AUTOSAR XML (schema 00048)
package /VehicleProject
  system System
    system mapping System_MPPNG
    root-software-compositions:
      root sw composition prototype EcuSwComposition: software-composition=ECU_Composition
package /ECUCompositionTypes
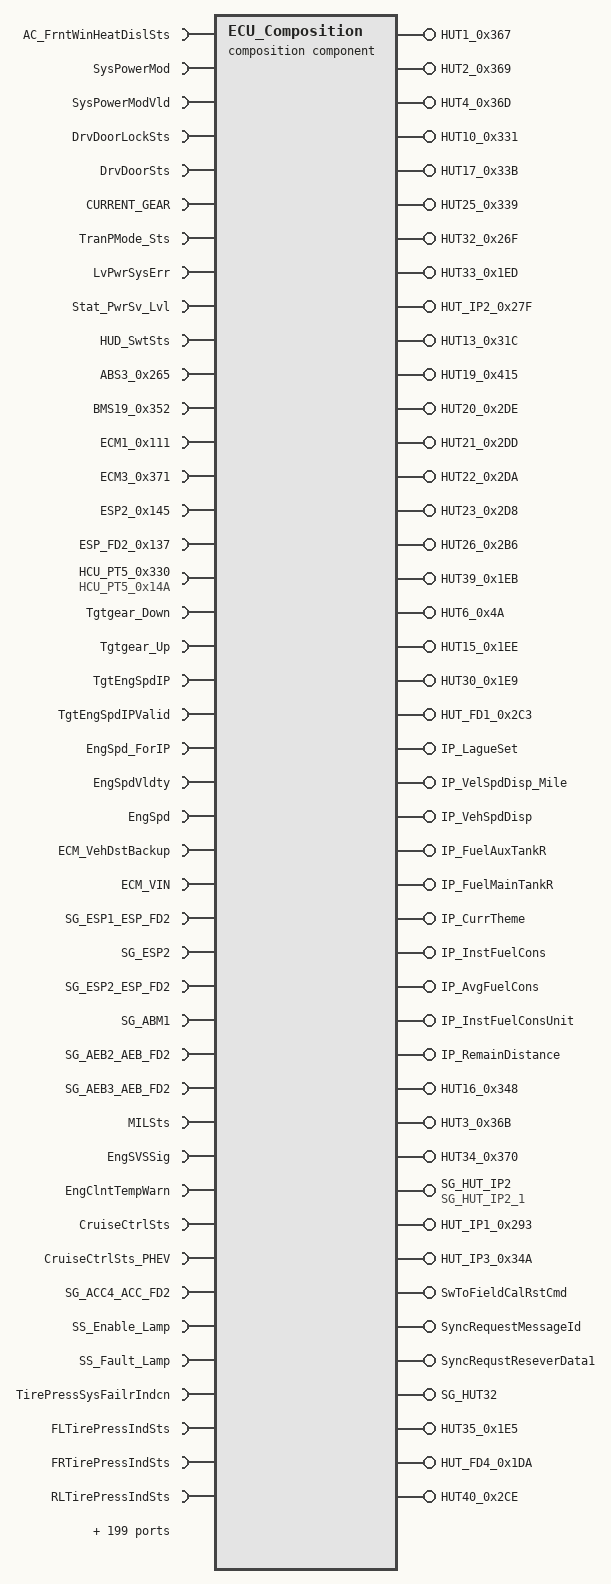
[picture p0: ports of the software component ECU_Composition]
  composition sw component type ECU_Composition
    79 x require port:
      AC_FrntWinHeatDislSts: nonqueued-receiver-com-spec{data-element=AC_FrntWinHeatDislSts, init-value=0}, required-interface=AC_FrntWinHeatDislSts
      SysPowerMod: nonqueued-receiver-com-spec{data-element=SysPowerMod, init-value=0}, required-interface=SysPowerMod
      SysPowerModVld: nonqueued-receiver-com-spec{data-element=SysPowerModVld, init-value=0}, required-interface=SysPowerModVld
      DrvDoorLockSts: nonqueued-receiver-com-spec{data-element=DrvDoorLockSts, init-value=0}, required-interface=DrvDoorLockSts
      DrvDoorSts: nonqueued-receiver-com-spec{data-element=DrvDoorSts, init-value=0}, required-interface=DrvDoorSts
      CURRENT_GEAR: nonqueued-receiver-com-spec{data-element=CURRENT_GEAR, init-value=0}, required-interface=CURRENT_GEAR
      TranPMode_Sts: nonqueued-receiver-com-spec{data-element=TranPMode_Sts, init-value=0}, required-interface=TranPMode_Sts
      LvPwrSysErr: nonqueued-receiver-com-spec{data-element=LvPwrSysErr, init-value=0}, required-interface=LvPwrSysErr
      Stat_PwrSv_Lvl: nonqueued-receiver-com-spec{data-element=Stat_PwrSv_Lvl, init-value=0}, required-interface=Stat_PwrSv_Lvl
      HUD_SwtSts: nonqueued-receiver-com-spec{data-element=HUD_SwtSts, init-value=1}, required-interface=HUD_SwtSts
      ABS3_0x265: nonqueued-receiver-com-spec{data-element=ABS3_0x265, init-value=16 x 0}, required-interface=ABS3_0x265
      BMS19_0x352: nonqueued-receiver-com-spec{data-element=BMS19_0x352, init-value=8 x 0}, required-interface=BMS19_0x352
      ECM1_0x111: nonqueued-receiver-com-spec{data-element=ECM1_0x111, init-value=8 x 0}, required-interface=ECM1_0x111
      ECM3_0x371: nonqueued-receiver-com-spec{data-element=ECM3_0x371, init-value=8 x 0}, required-interface=ECM3_0x371
      ESP2_0x145: nonqueued-receiver-com-spec{data-element=ESP2_0x145, init-value=16 x 0}, required-interface=ESP2_0x145
      ESP_FD2_0x137: nonqueued-receiver-com-spec{data-element=ESP_FD2_0x137, init-value=64 x 0}, required-interface=ESP_FD2_0x137
      HCU_PT5_0x330: nonqueued-receiver-com-spec{data-element=HCU_PT5_0x14A, init-value=8 x 0}, required-interface=HCU_PT5_0x14A
      Tgtgear_Down: nonqueued-receiver-com-spec{data-element=Tgtgear_Down, init-value=0}, required-interface=Tgtgear_Down
      Tgtgear_Up: nonqueued-receiver-com-spec{data-element=Tgtgear_Up, init-value=0}, required-interface=Tgtgear_Up
      TgtEngSpdIP: nonqueued-receiver-com-spec{data-element=TgtEngSpdIP, init-value=0}, required-interface=TgtEngSpdIP
      TgtEngSpdIPValid: nonqueued-receiver-com-spec{data-element=TgtEngSpdIPValid, init-value=0}, required-interface=TgtEngSpdIPValid
      EngSpd_ForIP: nonqueued-receiver-com-spec{data-element=EngSpd_ForIP, init-value=0}, required-interface=EngSpd_ForIP
      EngSpdVldty: nonqueued-receiver-com-spec{data-element=EngSpdVldty, init-value=2}, required-interface=EngSpdVldty
      EngSpd: nonqueued-receiver-com-spec{data-element=EngSpd, init-value=0}, required-interface=EngSpd
      ECM_VehDstBackup: nonqueued-receiver-com-spec{data-element=ECM_VehDstBackup, init-value=0}, required-interface=ECM_VehDstBackup
      ECM_VIN: nonqueued-receiver-com-spec{data-element=ECM19_0x3B5, init-value=8 x 0}, required-interface=ECM_VIN
      SG_ESP1_ESP_FD2: nonqueued-receiver-com-spec{data-element=SG_ESP1_ESP_FD2, uses-end-to-end-protection=true, alive-timeout=0.2, enable-update=true, handle-never-received=true, init-value=fields=[BTCActv_0x137:0, CheckSum_ESP1_0x137:0, dummy_ESP_FD2_16:0, dummy_ESP_FD2_17:0, dummy_ESP_FD2_18:0, dummy_ESP_FD2_19:0, dummy_ESP_FD2_20:0, ESP_MasterCylBrkPress_0x137:0, ESP_MasterCylBrkPressVld_0x137:0, ESPActvInfoLmp_0x137:0, ESPBrkLmpCtrl_0x137:0, ESPFailSts_0x137:0, ESPFuncOffSts_0x137:0, MSRActv_0x137:0, PTCActv_0x137:0, RollingCounter_ESP1_0x137:0, VDCActv_0x137:0]}, required-interface=SG_ESP1_ESP_FD2
      SG_ESP2: nonqueued-receiver-com-spec{data-element=SG_ESP2, uses-end-to-end-protection=true, alive-timeout=0.2, enable-update=true, handle-never-received=true, init-value=fields=[DrivingModDis:0, DrivingModReq_ESP:0, TAB_Available:0, TAB_Sts:0, ABAActv_0x145:0, ABAavailable_0x145:0, ABPActv_0x145:0, ABPAvailable_0x145:0, AEBAvailable_0x145:0, AEBBAActv_0x145:0, AEBIBActv_0x145:0, AVHErrSts_0x145:0, AVHSts_0x145:0, AWBActv_0x145:0, AWBAvailable_0x145:0, BrkDskOvrheatd_0x145:0, CDDActv_0x145:0, CDDAvailable_0x145:0, CDPActv_0x145:0, CheckSum_ESP2_0x145:0, dummy_ESP2_0:0, dummy_ESP2_1:0, dummy_ESP2_2:0, dummy_ESP2_3:0, dummy_ESP2_4:0, dummy_ESP2_5:0, dummy_ESP2_6:0, dummy_ESP2_7:0, HDCCtrl_0x145:0, HDCFault_0x145:0, NoBrkForce_0x145:0, RollingCounter_ESP2_0x145:0, VehStandstill_0x145:0]}, required-interface=SG_ESP2
      SG_ESP2_ESP_FD2: nonqueued-receiver-com-spec{data-element=SG_ESP2_ESP_FD2, uses-end-to-end-protection=true, alive-timeout=0.2, enable-update=true, handle-never-received=true, init-value=fields=[ABAActv_0x137:0, ABAavailable_0x137:0, ABPActv_0x137:0, ABPAvailable_0x137:0, AEBAvailable_0x137:0, AEBBAActv_0x137:0, AEBIBActv_0x137:0, AVHErrSts_0x137:0, AVHSts_0x137:0, AWBActv_0x137:0, AWBAvailable_0x137:0, BrkDskOvrheatd_0x137:0, CDDActv_0x137:0, CDDAvailable_0x137:0, CDPActv_0x137:0, CheckSum_ESP2_0x137:0, dummy_ESP_FD2_8:0, dummy_ESP_FD2_9:0, dummy_ESP_FD2_10:0, dummy_ESP_FD2_11:0, dummy_ESP_FD2_12:0, dummy_ESP_FD2_13:0, dummy_ESP_FD2_14:0, dummy_ESP_FD2_15:0, HDCCtrl_0x137:0, HDCFault_0x137:0, NoBrkForce_0x137:0, RollingCounter_ESP2_0x137:0, VehStandstill_0x137:0]}, required-interface=SG_ESP2_ESP_FD2
      SG_ABM1: nonqueued-receiver-com-spec{data-element=SG_ABM1, uses-end-to-end-protection=true, alive-timeout=5, enable-update=true, handle-never-received=true, init-value=fields=[AirbFailLmpCmd:1, CheckSum_ABM1:0, DrvSBR:1, DrvSBR_Visual:1, PassSBR:1, PassSBR_Visual:1, RollingCounter_ABM1:0, SecRowLSBR:1, SecRowLSBR_Visual:1, SecRowMidSBR:1, SecRowMidSBR_Visual:1, SecRowRSBR:1, SecRowRSBR_Visual:1, CrashOutputSts:0, dummy_ABM1_0:0, dummy_ABM1_1:0, dummy_ABM1_2:0, dummy_ABM1_3:0, dummy_ABM1_4:0, dummy_ABM1_5:0]}, required-interface=SG_ABM1
      SG_AEB2_AEB_FD2: nonqueued-receiver-com-spec{data-element=SG_AEB2_AEB_FD2, uses-end-to-end-protection=true, alive-timeout=0.5, enable-update=true, handle-never-received=true, init-value=fields=[AEB_JA_Resp:1, AEB_PedResp:1, AEB_VehResp:1, Checksum_AEB2:0, FCW_Snvty:0, RollingCounter_AEB2:0, dummy_AEB_FD2_8:0, dummy_AEB_FD2_9:0, dummy_AEB_FD2_10:0, dummy_AEB_FD2_11:0, dummy_AEB_FD2_12:0, dummy_AEB_FD2_13:0, dummy_AEB_FD2_14:0]}, required-interface=SG_AEB2_AEB_FD2
      SG_AEB3_AEB_FD2: nonqueued-receiver-com-spec{data-element=SG_AEB3_AEB_FD2, uses-end-to-end-protection=true, alive-timeout=0.5, enable-update=true, handle-never-received=true, init-value=fields=[AEB_JA_Warn:0, AEB_JABrkTrig:0, AEB_JAFuncSts:0, AEB_PedTrig:0, AEB_VehTrig:0, Checksum_AEB3:0, FCW_AEB_PedFctSts:0, FCW_AEB_VehFctSts:0, FCW_Warn:0, RollingCounter_AEB3:0, dummy_AEB_FD2_15:0, dummy_AEB_FD2_16:0, dummy_AEB_FD2_17:0, dummy_AEB_FD2_18:0, dummy_AEB_FD2_19:0, dummy_AEB_FD2_20:0, dummy_AEB_FD2_21:0]}, required-interface=SG_AEB3_AEB_FD2
      MILSts: nonqueued-receiver-com-spec{data-element=MILSts, init-value=0}, required-interface=MILSts
      EngSVSSig: nonqueued-receiver-com-spec{data-element=EngSVSSig, init-value=0}, required-interface=EngSVSSig
      EngClntTempWarn: nonqueued-receiver-com-spec{data-element=EngClntTempWarn, init-value=0}, required-interface=EngClntTempWarn
      CruiseCtrlSts: nonqueued-receiver-com-spec{data-element=CruiseCtrlSts, init-value=0}, required-interface=CruiseCtrlSts
      CruiseCtrlSts_PHEV: nonqueued-receiver-com-spec{data-element=CruiseCtrlSts_PHEV, init-value=0}, required-interface=CruiseCtrlSts_PHEV
      SG_ACC4_ACC_FD2: nonqueued-receiver-com-spec{data-element=SG_ACC4_ACC_FD2, uses-end-to-end-protection=true, alive-timeout=1, enable-update=true, handle-never-received=true, init-value=fields=[ACC_FctSts:0, ACC_InterSysInfoDisp:0, ACC_ModDisp:0, ACC_ObjDetecte:0, ACC_SpdSetValue:255, ACC_TakeOverReq:0, ACC_TgtObjBarDisp:0, ACC_TimeGapSet:0, Checksum_ACC4:0, ISL_InterSysInfoDisp:0, RollingCounter_ACC4:0, TJA_ACC_SelSts:0, TJA_ICA_InterSysInfoDisp:0, TJA_ICA_ModDisp:0, CruCha_ModDisp:0, CruChar_InterSysInfoDisp:0, Longctrl_HazActv:0, dummy_ACC_FD2_8:0, dummy_ACC_FD2_9:0, dummy_ACC_FD2_10:0]}, required-interface=SG_ACC4_ACC_FD2
      SS_Enable_Lamp: nonqueued-receiver-com-spec{data-element=SS_Enable_Lamp, init-value=0}, required-interface=SS_Enable_Lamp
      SS_Fault_Lamp: nonqueued-receiver-com-spec{data-element=SS_Fault_Lamp, init-value=0}, required-interface=SS_Fault_Lamp
      TirePressSysFailrIndcn: nonqueued-receiver-com-spec{data-element=TirePressSysFailrIndcn, init-value=0}, required-interface=TirePressSysFailrIndcn
      FLTirePressIndSts: nonqueued-receiver-com-spec{data-element=FLTirePressIndSts, init-value=0}, required-interface=FLTirePressIndSts
      FRTirePressIndSts: nonqueued-receiver-com-spec{data-element=FRTirePressIndSts, init-value=0}, required-interface=FRTirePressIndSts
      RLTirePressIndSts: nonqueued-receiver-com-spec{data-element=RLTirePressIndSts, init-value=0}, required-interface=RLTirePressIndSts
      RRTirePressIndSts: nonqueued-receiver-com-spec{data-element=RRTirePressIndSts, init-value=0}, required-interface=RRTirePressIndSts
      FLTireTempSts: nonqueued-receiver-com-spec{data-element=FLTireTempSts, init-value=0}, required-interface=FLTireTempSts
      FRTireTempSts: nonqueued-receiver-com-spec{data-element=FRTireTempSts, init-value=0}, required-interface=FRTireTempSts
      RLTireTempSts: nonqueued-receiver-com-spec{data-element=RLTireTempSts, init-value=0}, required-interface=RLTireTempSts
      RRTireTempSts: nonqueued-receiver-com-spec{data-element=RRTireTempSts, init-value=0}, required-interface=RRTireTempSts
      SG_EPS1_FD1: nonqueued-receiver-com-spec{data-element=SG_EPS1_FD1, uses-end-to-end-protection=true, alive-timeout=0.2, enable-update=true, handle-never-received=true, init-value=fields=[CheckSum_EPS1_0x147:0, dummy_EPS_FD1_0:0, dummy_EPS_FD1_1:0, dummy_EPS_FD1_2:0, dummy_EPS_FD1_3:0, dummy_EPS_FD1_4:0, dummy_EPS_FD1_5:0, dummy_EPS_FD1_6:0, dummy_EPS_FD1_7:0, EPS_FailSts_0x147:0, EPS_SteerMod_0x147:0, EPS_TrqSnsrSts_0x147:0, RollingCounter_EPS1_0x147:0]}, required-interface=SG_EPS1_FD1
      SG_IFC4_IFC_FD2: nonqueued-receiver-com-spec{data-element=SG_IFC4_IFC_FD2, uses-end-to-end-protection=true, alive-timeout=0.5, enable-update=true, handle-never-received=true, init-value=fields=[CameraBlockageSts:0, Checksum_IFC4:0, ELKMainState:0, IFC_Handsoffwarn:0, IFCCalibrationSts:0, LaneAvailability:0, LDW_LKAWarn:0, LSSErrSts:0, LSSFuncSts:0, LSSIntervention:0, RollingCounter_IFC4:0, TJA_FollowSts:0, AESintervention:0, ESSintervention:0, dummy_IFC_FD2_13:0, dummy_IFC_FD2_14:0, dummy_IFC_FD2_15:0, ELKActSts:0, IntelligentEvaActSts:0, LCKStsIndcr:0]}, required-interface=SG_IFC4_IFC_FD2
      ESP_HMI_WarningOn: nonqueued-receiver-com-spec{data-element=ESP_HMI_WarningOn, init-value=0}, required-interface=ESP_HMI_WarningOn
      IB_Warn: nonqueued-receiver-com-spec{data-element=IB_Warn, init-value=0}, required-interface=IB_Warn
      FFogLmpSts_F_Pbox: nonqueued-receiver-com-spec{data-element=FFogLmpSts_F_Pbox, init-value=0}, required-interface=FFogLmpSts_F_Pbox
      RFogLmpFailSts_R_Pbox: nonqueued-receiver-com-spec{data-element=RFogLmpFailSts_R_Pbox, init-value=0}, required-interface=RFogLmpFailSts_R_Pbox
      SG_HC1: nonqueued-receiver-com-spec{data-element=SG_HC1, uses-end-to-end-protection=true, alive-timeout=1, enable-update=true, handle-never-received=true, init-value=fields=[ADBstatus:0, ALS_FailSts:0, Checksum_HC1:0, HighBeamSts_HC:0, LeftHighBeamFailSts:0, LeftLowBeamFailSts:0, RightHighBeamFailSts:0, RightLowBeamFailSts:0, RollingCounter_HC1:0, dummy_HC1_0:0, dummy_HC1_1:0, dummy_HC1_2:0, dummy_HC1_3:0, dummy_HC1_4:0, dummy_HC1_5:0]}, required-interface=SG_HC1
      LTurnLmpFailSts: nonqueued-receiver-com-spec{data-element=LTurnLmpFailSts, init-value=0}, required-interface=LTurnLmpFailSts
      LTurnLmpSts_R_Pbox: nonqueued-receiver-com-spec{data-element=LTurnLmpSts_R_Pbox, init-value=0}, required-interface=LTurnLmpSts_R_Pbox
      RTurnLmpSts_R_Pbox: nonqueued-receiver-com-spec{data-element=RTurnLmpSts_R_Pbox, init-value=0}, required-interface=RTurnLmpSts_R_Pbox
      PosnLmpOutpSts_R_Pbox: nonqueued-receiver-com-spec{data-element=PosnLmpOutpSts_R_Pbox, init-value=0}, required-interface=PosnLmpOutpSts_R_Pbox
      TrailerSts: nonqueued-receiver-com-spec{data-element=TrailerSts, init-value=0}, required-interface=TrailerSts
      HiLowBeamSts: nonqueued-receiver-com-spec{data-element=HiLowBeamSts, init-value=0}, required-interface=HiLowBeamSts
      HCU_EVLmpSts: nonqueued-receiver-com-spec{data-element=HCU_EVLmpSts, init-value=0}, required-interface=HCU_EVLmpSts
      HCU_ChrgSysLmpSts: nonqueued-receiver-com-spec{data-element=HCU_ChrgSysLmpSts, init-value=0}, required-interface=HCU_ChrgSysLmpSts
      ParkLmpSts_R_Pbox: nonqueued-receiver-com-spec{data-element=ParkLmpSts_R_Pbox, init-value=0}, required-interface=ParkLmpSts_R_Pbox
      TgtRcprtnTrqSts: nonqueued-receiver-com-spec{data-element=TgtRcprtnTrqSts, init-value=0}, required-interface=TgtRcprtnTrqSts
      CCO_Active: nonqueued-receiver-com-spec{data-element=CCO_Active, init-value=0}, required-interface=CCO_Active
      RSDS_CTA_Actv: nonqueued-receiver-com-spec{data-element=RSDS_CTA_Actv, init-value=0}, required-interface=RSDS_CTA_Actv
      RSDS_ErrSts: nonqueued-receiver-com-spec{data-element=RSDS_ErrSts, init-value=0}, required-interface=RSDS_ErrSts
      RemoteModSts: nonqueued-receiver-com-spec{data-element=RemoteModSts, init-value=0}, required-interface=RemoteModSts
      KL30BRelaySts: nonqueued-receiver-com-spec{data-element=KL30BRelaySts, init-value=0}, required-interface=KL30BRelaySts
      BMS_SOCLowWarn: nonqueued-receiver-com-spec{data-element=BMS_SOCLowWarn, init-value=0}, required-interface=BMS_SOCLowWarn
      TSRSts: nonqueued-receiver-com-spec{data-element=TSRSts, init-value=0}, required-interface=TSRSts
      TSRSpdLimSts: nonqueued-receiver-com-spec{data-element=TSRSpdLimSts, init-value=0}, required-interface=TSRSpdLimSts
      TSRSpdLim: nonqueued-receiver-com-spec{data-element=TSRSpdLim, init-value=0}, required-interface=TSRSpdLim
      TSRSpdLimWarn: nonqueued-receiver-com-spec{data-element=TSRSpdLimWarn, init-value=0}, required-interface=TSRSpdLimWarn
      TSRTrfcSignVal: nonqueued-receiver-com-spec{data-element=TSRTrfcSignVal, init-value=0}, required-interface=TSRTrfcSignVal
      AC2_0x385: nonqueued-receiver-com-spec{data-element=AC2_0x385, init-value=8 x 0}, required-interface=AC2_0x385
      AC1_0x29D: nonqueued-receiver-com-spec{data-element=AC1_0x29D, init-value=8 x 0}, required-interface=AC1_0x29D
    provide port HUT1_0x367: nonqueued-sender-com-spec{data-element=HUT1_0x367, init-value=8 x 0}, provided-interface=HUT1_0x367
    42 x require port:
      ACC_FD2_0x2AB: nonqueued-receiver-com-spec{data-element=ACC_FD2_0x2AB, init-value=64 x 0}, required-interface=ACC_FD2_0x2AB
      AEB_FD2_0x227: nonqueued-receiver-com-spec{data-element=AEB_FD2_0x227, init-value=64 x 0}, required-interface=AEB_FD2_0x227
      BCM1_0x319: nonqueued-receiver-com-spec{data-element=BCM1_0x319, init-value=16 x 0}, required-interface=BCM1_0x319
      BCM3_0x345: nonqueued-receiver-com-spec{data-element=BCM3_0x345, init-value=16 x 0}, required-interface=BCM3_0x345
      BCM8_0x29F: nonqueued-receiver-com-spec{data-element=BCM8_0x29F, init-value=8 x 0}, required-interface=BCM8_0x29F
      BMS4_0xF1: nonqueued-receiver-com-spec{data-element=BMS4_0xF1, init-value=8 x 0}, required-interface=BMS4_0xF1
      BMS30_0x3F1: nonqueued-receiver-com-spec{data-element=BMS30_0x3F1, init-value=8 x 0}, required-interface=BMS30_0x3F1
      BMS35_0x2C4: nonqueued-receiver-com-spec{data-element=BMS35_0x2C4, init-value=8 x 0}, required-interface=BMS35_0x2C4
      CP1_0x35E: nonqueued-receiver-com-spec{data-element=CP1_0x35E, init-value=8 x 0}, required-interface=CP1_0x35E
      CSA1_0x165: nonqueued-receiver-com-spec{data-element=CSA1_0x165, init-value=8 x 0}, required-interface=CSA1_0x165
      CSA2_0xA1: nonqueued-receiver-com-spec{data-element=CSA2_0xA1, init-value=8 x 0}, required-interface=CSA2_0xA1
      CSA3_0x244: nonqueued-receiver-com-spec{data-element=CSA3_0x244, init-value=8 x 0}, required-interface=CSA3_0x244
      DCT5_0x221: nonqueued-receiver-com-spec{data-element=DCT5_0x221, init-value=8 x 0}, required-interface=DCT5_0x221
      DCT7_0x235: nonqueued-receiver-com-spec{data-element=DCT7_0x235, init-value=16 x 0}, required-interface=DCT7_0x235
      DDCM1_0x2CA: nonqueued-receiver-com-spec{data-element=DDCM1_0x2CA, init-value=8 x 0}, required-interface=DDCM1_0x2CA
      DHT_FD1_0xC1: nonqueued-receiver-com-spec{data-element=DHT_FD1_0xC1, init-value=64 x 0}, required-interface=DHT_FD1_0xC1
      DMS_FD1_0x24D: nonqueued-receiver-com-spec{data-element=DMS_FD1_0x24D, init-value=64 x 0}, required-interface=DMS_FD1_0x24D
      ECM2_0x271: nonqueued-receiver-com-spec{data-element=ECM2_0x271, init-value=8 x 0}, required-interface=ECM2_0x271
      ECM_PT7_0x117: nonqueued-receiver-com-spec{data-element=ECM_PT7_0x117, init-value=8 x 0}, required-interface=ECM_PT7_0x117
      EEM1_0x2A8: nonqueued-receiver-com-spec{data-element=EEM1_0x2A8, init-value=8 x 0}, required-interface=EEM1_0x2A8
      ELD1_0x152: nonqueued-receiver-com-spec{data-element=ELD1_0x152, init-value=8 x 0}, required-interface=ELD1_0x152
      EPB1_0x16B: nonqueued-receiver-com-spec{data-element=EPB1_0x16B, init-value=8 x 0}, required-interface=EPB1_0x16B
      EPS1_0x168: nonqueued-receiver-com-spec{data-element=EPS1_0x168, init-value=8 x 0}, required-interface=EPS1_0x168
      EPS_FD1_0x147: nonqueued-receiver-com-spec{data-element=EPS_FD1_0x147, init-value=64 x 0}, required-interface=EPS_FD1_0x147
      ESCL2_0x303: nonqueued-receiver-com-spec{data-element=ESCL2_0x303, init-value=8 x 0}, required-interface=ESCL2_0x303
      ESP1_0x149: nonqueued-receiver-com-spec{data-element=ESP1_0x149, init-value=16 x 0}, required-interface=ESP1_0x149
      ESP8_0x170: nonqueued-receiver-com-spec{data-element=ESP8_0x170, init-value=8 x 0}, required-interface=ESP8_0x170
      ESP10_0xD8: nonqueued-receiver-com-spec{data-element=ESP10_0xD8, init-value=8 x 0}, required-interface=ESP10_0xD8
      ESP11_0xC8: nonqueued-receiver-com-spec{data-element=ESP11_0xC8, init-value=8 x 0}, required-interface=ESP11_0xC8
      F_PBox1_0x19B: nonqueued-receiver-com-spec{data-element=F_PBox1_0x19B, init-value=8 x 0}, required-interface=F_PBox1_0x19B
      FPAS1_0x26D: nonqueued-receiver-com-spec{data-element=FPAS1_0x26D, init-value=8 x 0}, required-interface=FPAS1_0x26D
      Haldex1_0x251: nonqueued-receiver-com-spec{data-element=Haldex1_0x251, init-value=8 x 0}, required-interface=Haldex1_0x251
      HAP_FD1_0x15B: nonqueued-receiver-com-spec{data-element=HAP_FD1_0x15B, init-value=64 x 0}, required-interface=HAP_FD1_0x15B
      HAP_FD2_0x274: nonqueued-receiver-com-spec{data-element=HAP_FD2_0x274, init-value=64 x 0}, required-interface=HAP_FD2_0x274
      HAP_FD3_0x298: nonqueued-receiver-com-spec{data-element=HAP_FD3_0x298, init-value=64 x 0}, required-interface=HAP_FD3_0x298
      HC1_0x287: nonqueued-receiver-com-spec{data-element=HC1_0x287, init-value=8 x 0}, required-interface=HC1_0x287
      HCU_HC6_0x314: nonqueued-receiver-com-spec{data-element=HCU_HC6_0x314, init-value=8 x 0}, required-interface=HCU_HC6_0x314
      HCU_HC7_0x3C2: nonqueued-receiver-com-spec{data-element=HCU_HC7_0x3C2, init-value=8 x 0}, required-interface=HCU_HC7_0x3C2
      HCU_PT4_0x2FA: nonqueued-receiver-com-spec{data-element=HCU_PT4_0x2FA, init-value=8 x 0}, required-interface=HCU_PT4_0x2FA
      HCU_PT7_0x248: nonqueued-receiver-com-spec{data-element=HCU_PT7_0x248, init-value=8 x 0}, required-interface=HCU_PT7_0x248
      HCU_PT8_0x1C0: nonqueued-receiver-com-spec{data-element=HCU_PT8_0x1C0, init-value=8 x 0}, required-interface=HCU_PT8_0x1C0
      HUD1_0x325: nonqueued-receiver-com-spec{data-element=HUD1_0x325, init-value=8 x 0}, required-interface=HUD1_0x325
    8 x provide port:
      HUT2_0x369: nonqueued-sender-com-spec{data-element=HUT2_0x369, init-value=8 x 0}, provided-interface=HUT2_0x369
      HUT4_0x36D: nonqueued-sender-com-spec{data-element=HUT4_0x36D, init-value=8 x 0}, provided-interface=HUT4_0x36D
      HUT10_0x331: nonqueued-sender-com-spec{data-element=HUT10_0x331, init-value=8 x 0}, provided-interface=HUT10_0x331
      HUT17_0x33B: nonqueued-sender-com-spec{data-element=HUT17_0x33B, init-value=8 x 0}, provided-interface=HUT17_0x33B
      HUT25_0x339: nonqueued-sender-com-spec{data-element=HUT25_0x339, init-value=8 x 0}, provided-interface=HUT25_0x339
      HUT32_0x26F: nonqueued-sender-com-spec{data-element=HUT32_0x26F, init-value=8 x 0}, provided-interface=HUT32_0x26F
      HUT33_0x1ED: nonqueued-sender-com-spec{data-element=HUT33_0x1ED, init-value=8 x 0}, provided-interface=HUT33_0x1ED
      HUT_IP2_0x27F: nonqueued-sender-com-spec{data-element=HUT_IP2_0x27F, init-value=16 x 0}, provided-interface=HUT_IP2_0x27F
    60 x require port:
      Ibooster_FD2_0x120: nonqueued-receiver-com-spec{data-element=Ibooster_FD2_0x120, init-value=64 x 0}, required-interface=Ibooster_FD2_0x120
      IFC_FD3_0x2CF: nonqueued-receiver-com-spec{data-element=IFC_FD3_0x2CF, init-value=64 x 0}, required-interface=IFC_FD3_0x2CF
      OBC1_0x316: nonqueued-receiver-com-spec{data-element=OBC1_0x316, init-value=8 x 0}, required-interface=OBC1_0x316
      OBC2_0x317: nonqueued-receiver-com-spec{data-element=OBC2_0x317, init-value=8 x 0}, required-interface=OBC2_0x317
      PDCM1_0x2CD: nonqueued-receiver-com-spec{data-element=PDCM1_0x2CD, init-value=8 x 0}, required-interface=PDCM1_0x2CD
      PEPS2_0x295: nonqueued-receiver-com-spec{data-element=PEPS2_0x295, init-value=8 x 0}, required-interface=PEPS2_0x295
      PEPS4_0x302: nonqueued-receiver-com-spec{data-element=PEPS4_0x302, init-value=8 x 0}, required-interface=PEPS4_0x302
      R_PBox1_0x19C: nonqueued-receiver-com-spec{data-element=R_PBox1_0x19C, init-value=16 x 0}, required-interface=R_PBox1_0x19C
      RPAS1_0x26E: nonqueued-receiver-com-spec{data-element=RPAS1_0x26E, init-value=8 x 0}, required-interface=RPAS1_0x26E
      RSDS_FD1_0x16F: nonqueued-receiver-com-spec{data-element=RSDS_FD1_0x16F, init-value=64 x 0}, required-interface=RSDS_FD1_0x16F
      SCM1_0x2D1: nonqueued-receiver-com-spec{data-element=SCM1_0x2D1, init-value=8 x 0}, required-interface=SCM1_0x2D1
      T_Box_FD1_0x33: nonqueued-receiver-com-spec{data-element=T_Box_FD1_0x33, init-value=16 x 0}, required-interface=T_Box_FD1_0x33
      T_Box_FD3_0x3E9: nonqueued-receiver-com-spec{data-element=T_Box_FD3_0x3E9, init-value=16 x 0}, required-interface=T_Box_FD3_0x3E9
      TPMS1_0x341: nonqueued-receiver-com-spec{data-element=TPMS1_0x341, init-value=16 x 0}, required-interface=TPMS1_0x341
      TPMS2_0x395: nonqueued-receiver-com-spec{data-element=TPMS2_0x395, init-value=16 x 0}, required-interface=TPMS2_0x395
      Trailer1_0x273: nonqueued-receiver-com-spec{data-element=Trailer1_0x273, init-value=8 x 0}, required-interface=Trailer1_0x273
      VSG1_0x2E1: nonqueued-receiver-com-spec{data-element=VSG1_0x2E1, init-value=8 x 0}, required-interface=VSG1_0x2E1
      WPC1_0x2BA: nonqueued-receiver-com-spec{data-element=WPC1_0x2BA, init-value=8 x 0}, required-interface=WPC1_0x2BA
      SG_IFC5_IFC_FD2: nonqueued-receiver-com-spec{data-element=SG_IFC5_IFC_FD2, init-value=fields=[Checksum_IFC5:0, IFC_LaneCurve:2047, IFC_LeLane_dy:2496, IFC_LeLaneTyp:0, IFC_NextLeLaneTyp:0, IFC_NextRiLaneTyp:0, IFC_RiLane_dy:2496, IFC_RiLaneTyp:0, RollingCounter_IFC5:0, dummy_IFC_FD2_16:0]}, required-interface=SG_IFC5_IFC_FD2
      RSDS_IPSoundReq: nonqueued-receiver-com-spec{data-element=RSDS_IPSoundReq, init-value=0}, required-interface=RSDS_IPSoundReq
      TSRSpdLimCfdc: nonqueued-receiver-com-spec{data-element=TSRSpdLimCfdc, init-value=0}, required-interface=TSRSpdLimCfdc
      PASWorkCmd: nonqueued-receiver-com-spec{data-element=PASWorkCmd, init-value=0}, required-interface=PASWorkCmd
      APS_FLSideSnsrFailSts: nonqueued-receiver-com-spec{data-element=APS_FLSideSnsrFailSts, init-value=0}, required-interface=APS_FLSideSnsrFailSts
      APS_FRSideSnsrFailSts: nonqueued-receiver-com-spec{data-element=APS_FRSideSnsrFailSts, init-value=0}, required-interface=APS_FRSideSnsrFailSts
      APS_RLSideSnsrFailSts: nonqueued-receiver-com-spec{data-element=APS_RLSideSnsrFailSts, init-value=0}, required-interface=APS_RLSideSnsrFailSts
      APS_RRSideSnsrFailSts: nonqueued-receiver-com-spec{data-element=APS_RRSideSnsrFailSts, init-value=0}, required-interface=APS_RRSideSnsrFailSts
      SDW_SoundIndcn: nonqueued-receiver-com-spec{data-element=SDW_SoundIndcn, init-value=0}, required-interface=SDW_SoundIndcn
      SDWActiveSts: nonqueued-receiver-com-spec{data-element=SDWActiveSts, init-value=0}, required-interface=SDWActiveSts
      APS_WorkSts: nonqueued-receiver-com-spec{data-element=APS_WorkSts, init-value=0}, required-interface=APS_WorkSts
      APS_SysSoundIndcn: nonqueued-receiver-com-spec{data-element=APS_SysSoundIndcn, init-value=0}, required-interface=APS_SysSoundIndcn
      RPAS_WorkSts_FD: nonqueued-receiver-com-spec{data-element=RPAS_WorkSts_FD, init-value=0}, required-interface=RPAS_WorkSts_FD
      RPAS_SoundIndcn_FD: nonqueued-receiver-com-spec{data-element=RPAS_SoundIndcn_FD, init-value=0}, required-interface=RPAS_SoundIndcn_FD
      FLTirePress: nonqueued-receiver-com-spec{data-element=FLTirePress, init-value=0}, required-interface=FLTirePress
      FRTirePress: nonqueued-receiver-com-spec{data-element=FRTirePress, init-value=0}, required-interface=FRTirePress
      FRTireTemp: nonqueued-receiver-com-spec{data-element=FRTireTemp, init-value=0}, required-interface=FRTireTemp
      FLTireTemp: nonqueued-receiver-com-spec{data-element=FLTireTemp, init-value=0}, required-interface=FLTireTemp
      RLTireTemp: nonqueued-receiver-com-spec{data-element=RLTireTemp, init-value=0}, required-interface=RLTireTemp_1
      RLTirePress: nonqueued-receiver-com-spec{data-element=RLTirePress, init-value=0}, required-interface=RLTirePress_1
      RRTirePress: nonqueued-receiver-com-spec{data-element=RRTirePress, init-value=0}, required-interface=RRTirePress
      RRTireTemp: nonqueued-receiver-com-spec{data-element=RRTireTemp, init-value=0}, required-interface=RRTireTemp
      IFC_FD2_0x23D: nonqueued-receiver-com-spec{data-element=IFC_FD2_0x23D, init-value=64 x 0}, required-interface=IFC_FD2_0x23D
      ABM1_0x351: nonqueued-receiver-com-spec{data-element=ABM1_0x351, init-value=16 x 0}, required-interface=ABM1_0x351
      BMS_IntelEngIdlChrgnSts: nonqueued-receiver-com-spec{data-element=BMS_IntelEngIdlChrgnSts, init-value=0}, required-interface=BMS_IntelEngIdlChrgnSts_1
      BMS_BattHeatRunaway: nonqueued-receiver-com-spec{data-element=BMS_BattHeatRunaway, init-value=0}, required-interface=BMS_BattHeatRunaway_1
      GentrWarnLmpSts: nonqueued-receiver-com-spec{data-element=GentrWarnLmpSts, init-value=0}, required-interface=GentrWarnLmpSts
      FPAS_SoundIndcn_FD: nonqueued-receiver-com-spec{data-element=FPAS_SoundIndcn_FD, init-value=0}, required-interface=FPAS_SoundIndcn_FD
      FPAS_WorkSts_FD: nonqueued-receiver-com-spec{data-element=FPAS_WorkSts_FD, init-value=0}, required-interface=FPAS_WorkSts_FD
      TGS_LEVER: nonqueued-receiver-com-spec{data-element=TGS_LEVER, init-value=14}, required-interface=TGS_LEVER
      IFC_FD5_0x19F: nonqueued-receiver-com-spec{data-element=IFC_FD5_0x19F, init-value=64 x 0}, required-interface=IFC_FD5_0x19F
      IFC_FD6_0x222: nonqueued-receiver-com-spec{data-element=IFC_FD6_0x222, init-value=64 x 0}, required-interface=IFC_FD6_0x222
      CR_FD1_0x15E: nonqueued-receiver-com-spec{data-element=CR_FD1_0x15E, init-value=64 x 0}, required-interface=CR_FD1_0x15E
      AntitheftSts: nonqueued-receiver-com-spec{data-element=AntitheftSts, init-value=0}, required-interface=AntitheftSts
      AMP2_0x3E3: nonqueued-receiver-com-spec{data-element=AMP2_0x3E3, init-value=16 x 0}, required-interface=AMP2_0x3E3
      AMP3_0x3E5: nonqueued-receiver-com-spec{data-element=AMP3_0x3E5, init-value=8 x 0}, required-interface=AMP3_0x3E5
      BCM12_0x238: nonqueued-receiver-com-spec{data-element=BCM12_0x238, init-value=8 x 0}, required-interface=BCM12_0x238
      DSM1_0x2C1: nonqueued-receiver-com-spec{data-element=DSM1_0x2C1, init-value=8 x 0}, required-interface=DSM1_0x2C1
      GW_FD1_0x2BB: nonqueued-receiver-com-spec{data-element=GW_FD1_0x2BB, init-value=64 x 0}, required-interface=GW_FD1_0x2BB
      RPAS2_0x2ED: nonqueued-receiver-com-spec{data-element=RPAS2_0x2ED, init-value=8 x 0}, required-interface=RPAS2_0x2ED
      RSDS_FD2_0x30A: nonqueued-receiver-com-spec{data-element=RSDS_FD2_0x30A, init-value=64 x 0}, required-interface=RSDS_FD2_0x30A
      TMCU_FD3_0x3C9: nonqueued-receiver-com-spec{data-element=TMCU_FD3_0x3C9, init-value=8 x 0}, required-interface=TMCU_FD3_0x3C9
    12 x provide port:
      HUT13_0x31C: nonqueued-sender-com-spec{data-element=HUT13_0x31C, init-value=8 x 0}, provided-interface=HUT13_0x31C
      HUT19_0x415: nonqueued-sender-com-spec{data-element=HUT19_0x415, init-value=8 x 0}, provided-interface=HUT19_0x415
      HUT20_0x2DE: nonqueued-sender-com-spec{data-element=HUT20_0x2DE, init-value=8 x 0}, provided-interface=HUT20_0x2DE
      HUT21_0x2DD: nonqueued-sender-com-spec{data-element=HUT21_0x2DD, init-value=8 x 0}, provided-interface=HUT21_0x2DD
      HUT22_0x2DA: nonqueued-sender-com-spec{data-element=HUT22_0x2DA, init-value=8 x 0}, provided-interface=HUT22_0x2DA
      HUT23_0x2D8: nonqueued-sender-com-spec{data-element=HUT23_0x2D8, init-value=8 x 0}, provided-interface=HUT23_0x2D8
      HUT26_0x2B6: nonqueued-sender-com-spec{data-element=HUT26_0x2B6, init-value=8 x 0}, provided-interface=HUT26_0x2B6
      HUT39_0x1EB: nonqueued-sender-com-spec{data-element=HUT39_0x1EB, init-value=8 x 0}, provided-interface=HUT39_0x1EB
      HUT6_0x4A: nonqueued-sender-com-spec{data-element=HUT6_0x4A, init-value=8 x 0}, provided-interface=HUT6_0x4A
      HUT15_0x1EE: nonqueued-sender-com-spec{data-element=HUT15_0x1EE, init-value=16 x 0}, provided-interface=HUT15_0x1EE
      HUT30_0x1E9: nonqueued-sender-com-spec{data-element=HUT30_0x1E9, init-value=8 x 0}, provided-interface=HUT30_0x1E9
      HUT_FD1_0x2C3: nonqueued-sender-com-spec{data-element=HUT_FD1_0x2C3, init-value=64 x 0}, provided-interface=HUT_FD1_0x2C3
    11 x require port:
      TMCU_ActSpd_RM: nonqueued-receiver-com-spec{data-element=TMCU_ActSpd_RM, init-value=20000}, required-interface=TMCU_ActSpd_RM
      FuelConsumption: nonqueued-receiver-com-spec{data-element=FuelConsumption, init-value=0}, required-interface=FuelConsumption
      FCTA_Warn: nonqueued-receiver-com-spec{data-element=FCTA_Warn, init-value=0}, required-interface=FCTA_Warn
      FCTBTrig: nonqueued-receiver-com-spec{data-element=FCTBTrig, init-value=0}, required-interface=FCTBTrig
      CR_BliSts: nonqueued-receiver-com-spec{data-element=CR_BliSts, init-value=0}, required-interface=CR_BliSts
      FCTA_B_FuncSts: nonqueued-receiver-com-spec{data-element=FCTA_B_FuncSts, init-value=0}, required-interface=FCTA_B_FuncSts
      SG_ACC8_ACC_FD2: nonqueued-receiver-com-spec{data-element=SG_ACC8_ACC_FD2, init-value=fields=[ADAS_DriverInloop_Monitor:0, Checksum_ACC8:0, HWA_InterSysInfoDisp:0, HWA_LaneChange:0, HWA_LaneChangeReq:0, HWA_ModDisp:0, HWA_warning:0, Longctrl_HCUTrqReq_DVR:0, RollingCounter_ACC8:0, dummy_ACC_FD2_11:0, dummy_ACC_FD2_12:0, dummy_ACC_FD2_13:0, dummy_ACC_FD2_14:0, dummy_ACC_FD2_15:0]}, required-interface=SG_ACC8_ACC_FD2
      SG_IFC3_IFC_FD2: nonqueued-receiver-com-spec{data-element=SG_IFC3_IFC_FD2, init-value=fields=[AESErrSts:0, AESResp:0, AESSts:0, Checksum_IFC3:0, ELKResp:0, ESS_Pedresp:0, ESS_Vehresp:0, ESSErrSts:0, ESSSts:0, IFCHUTInterface:0, IntelligentEvaResp:0, LCKResp:0, LDW_LKA_Snvty:0, LDWResp:0, LKAResp:0, LSSResp:0, LSSWarnFormResp:0, RollingCounter_IFC3:0, dummy_IFC_FD2_8:0, dummy_IFC_FD2_9:0, dummy_IFC_FD2_10:0, dummy_IFC_FD2_11:0, dummy_IFC_FD2_12:0]}, required-interface=SG_IFC3_IFC_FD2
      SG_ACC3_ACC_FD2: nonqueued-receiver-com-spec{data-element=SG_ACC3_ACC_FD2, init-value=fields=[ALC_InterSysInfoDisp:0, ALC_Resp:0, Checksum_ACC3:0, HWA_Resp:0, HWA_SnvtySet_Resp:0, ICA_HandsOffResp:0, ISL_Resp:0, Longctrl_Decel_Req_DVR:0, Longctrl_Decel_ReqValue_DVR:0, Longctrl_DecelToStopReq_DVR:0, Longctrl_DrvOFF_Req_DVR:0, Longctrl_EngTrqReq_DVR:32767, Longctrl_EngTrqReqActive_DVR:0, Longctrl_HCUTrqReqActive_DVR:0, Longctrl_ModSts_DVR:0, Longctrl_ParkShiftReq_DVR:0, Longctrl_VehHldReq_DVR:0, RollingCounter_ACC3:0, dummy_ACC_FD2_4:0, dummy_ACC_FD2_5:0, dummy_ACC_FD2_6:0, dummy_ACC_FD2_7:0]}, required-interface=SG_ACC3_ACC_FD2
      EngCoolantTemp: nonqueued-receiver-com-spec{data-element=EngCoolantTemp, init-value=0}, required-interface=EngCoolantTemp
      EngClntTempVldty: nonqueued-receiver-com-spec{data-element=EngClntTempVldty, init-value=2}, required-interface=EngClntTempVldty
    10 x provide port:
      IP_LagueSet: nonqueued-sender-com-spec{data-element=IP_LagueSet, init-value=15}, provided-interface=IP_LagueSet
      IP_VelSpdDisp_Mile: nonqueued-sender-com-spec{data-element=IP_VelSpdDisp_Mile, init-value=0}, provided-interface=IP_VelSpdDisp_Mile
      IP_VehSpdDisp: nonqueued-sender-com-spec{data-element=IP_VehSpdDisp, init-value=0}, provided-interface=IP_VehSpdDisp
      IP_FuelAuxTankR: nonqueued-sender-com-spec{data-element=IP_FuelAuxTankR, init-value=10}, provided-interface=IP_FuelAuxTankR
      IP_FuelMainTankR: nonqueued-sender-com-spec{data-element=IP_FuelMainTankR, init-value=10}, provided-interface=IP_FuelMainTankR
      IP_CurrTheme: nonqueued-sender-com-spec{data-element=IP_CurrTheme, init-value=4}, provided-interface=IP_CurrTheme
      IP_InstFuelCons: nonqueued-sender-com-spec{data-element=IP_InstFuelCons, init-value=16383}, provided-interface=IP_InstFuelCons
      IP_AvgFuelCons: nonqueued-sender-com-spec{data-element=IP_AvgFuelCons, init-value=4095}, provided-interface=IP_AvgFuelCons
      IP_InstFuelConsUnit: nonqueued-sender-com-spec{data-element=IP_InstFuelConsUnit, init-value=0}, provided-interface=IP_InstFuelConsUnit
      IP_RemainDistance: nonqueued-sender-com-spec{data-element=IP_RemainDistance, init-value=0}, provided-interface=IP_RemainDistance
    5 x require port:
      ACC_FD3_0x2B4: nonqueued-receiver-com-spec{data-element=ACC_FD3_0x2B4, init-value=64 x 0}, required-interface=ACC_FD3_0x2B4
      ABS1_0x231: nonqueued-receiver-com-spec{data-element=ABS1_0x231, init-value=8 x 0}, required-interface=ABS1_0x231
      ABS2_0x246: nonqueued-receiver-com-spec{data-element=ABS2_0x246, init-value=8 x 0}, required-interface=ABS2_0x246
      BCM6_0x28C: nonqueued-receiver-com-spec{data-element=BCM6_0x28C, init-value=8 x 0}, required-interface=BCM6_0x28C
      PLG_1_0x2FE: nonqueued-receiver-com-spec{data-element=PLG_1_0x2FE, init-value=8 x 0}, required-interface=PLG_1_0x2FE
    provide port HUT16_0x348: nonqueued-sender-com-spec{data-element=HUT16_0x348, init-value=8 x 0}, provided-interface=HUT16_0x348
    provide port HUT3_0x36B: nonqueued-sender-com-spec{data-element=HUT3_0x36B, init-value=8 x 0}, provided-interface=HUT3_0x36B
    provide port HUT34_0x370: nonqueued-sender-com-spec{data-element=HUT34_0x370, init-value=8 x 0}, provided-interface=HUT34_0x370
    5 x require port:
      SG_EPB1: nonqueued-receiver-com-spec{data-element=SG_EPB1, uses-end-to-end-protection=true, alive-timeout=0.2, enable-update=true, handle-never-received=true, init-value=fields=[CheckSum_EPB1:0, EPBErrSts:0, EPBRedLmpSts:0, EPBSts:0, EPBTextDisp:0, PressBrakePedalPointOut:0, RollingCounter_EPB1:0, dummy_EPB1_0:0, dummy_EPB1_1:0, dummy_EPB1_2:0, dummy_EPB1_3:0, dummy_EPB1_4:0, dummy_EPB1_5:0, dummy_EPB1_6:0, dummy_EPB1_7:0]}, required-interface=SG_EPB1
      SG_EPS1: nonqueued-receiver-com-spec{data-element=SG_EPS1, uses-end-to-end-protection=true, alive-timeout=0.2, enable-update=true, handle-never-received=true, init-value=fields=[CheckSum_EPS1_0x168:0, dummy_EPS1_0:0, dummy_EPS1_1:0, dummy_EPS1_2:0, dummy_EPS1_3:0, dummy_EPS1_4:0, dummy_EPS1_5:0, dummy_EPS1_6:0, dummy_EPS1_7:0, EPS_FailSts_0x168:0, EPS_SteerMod_0x168:0, EPS_TrqSnsrSts_0x168:1, RollingCounter_EPS1_0x168:0]}, required-interface=SG_EPS1
      SG_DCT7: nonqueued-receiver-com-spec{data-element=SG_DCT7, uses-end-to-end-protection=true, alive-timeout=0.5, enable-update=true, handle-never-received=true, init-value=fields=[CheckSum_DCT7:0, DCT_PrsBrk_Warn:0, DCT_RaceModeSts:0, DCT_ShftNotAlwd_Warn:0, DCT_ShftRecom_M:0, DrvAutoGearDisp:0, DrvWarnMsg:0, RollingCounter_DCT7:0, DrvFaiMsg_0x235:0, DrvGearDispSts_0x235:0, DrvModDisp_0x235:0, DrvModDispSts_0x235:0, dummy_DCT7_0:0, dummy_DCT7_1:0, dummy_DCT7_2:0, dummy_DCT7_3:0, dummy_DCT7_4:0, dummy_DCT7_5:0]}, required-interface=SG_DCT7
      SG_ABS3: nonqueued-receiver-com-spec{data-element=SG_ABS3, uses-end-to-end-protection=true, alive-timeout=0.2, enable-update=true, handle-never-received=true, init-value=fields=[ABSActv_0x265:0, ABSFailSts_0x265:1, CheckSum_ABS3_0x265:0, dummy_ABS3_0:0, dummy_ABS3_1:0, dummy_ABS3_2:0, dummy_ABS3_3:0, EBDActv_0x265:0, EBDFailSts_0x265:0, RollingCounter_ABS3_0x265:0, VehOdoInfo_0x265:0, VehOdoInfoSts_0x265:1, VehSpd_0x265:0, VehSpdVld_0x265:0]}, required-interface=SG_ABS3
      SG_ESP1: nonqueued-receiver-com-spec{data-element=SG_ESP1, uses-end-to-end-protection=true, alive-timeout=0.2, enable-update=true, handle-never-received=true, init-value=fields=[BTCActv_0x149:0, CheckSum_ESP1_0x149:0, dummy_ESP1_0:0, dummy_ESP1_1:0, dummy_ESP1_2:0, dummy_ESP1_3:0, dummy_ESP1_4:0, ESP_MasterCylBrkPress_0x149:0, ESP_MasterCylBrkPressVld_0x149:1, ESPActvInfoLmp_0x149:0, ESPBrkLmpCtrl_0x149:0, ESPFailSts_0x149:0, ESPFuncOffSts_0x149:0, MSRActv_0x149:0, PTCActv_0x149:0, RollingCounter_ESP1_0x149:0, VDCActv_0x149:0]}, required-interface=SG_ESP1
    provide port SG_HUT_IP2: nonqueued-sender-com-spec{data-element=SG_HUT_IP2, uses-end-to-end-protection=true, init-value=fields=[CheckSum_IP2:0, IP_ABMWarnLmpFailrSts:0, IP_ACCErr:0, IP_BattChrgLmpSts:0, IP_DrvSeatBeltWarnLmpFailSts:0, IP_EngOilPressLowLmpSts:0, IP_Err:0, IP_FuelLvlInfo:0, IP_FuelLvlLowLmpSts:0, IP_PassSeatBeltWarnLmpFailSts:0, IP_VehSpdUnit:0, IP_VehTotDistance:0, IP_VehTotDistanceValid:0, IP_VINcompr:0, RollingCounter_IP2:0]}, provided-interface=SG_HUT_IP2_1
    require port SG_ABS3_ESP_FD2: nonqueued-receiver-com-spec{data-element=SG_ABS3_ESP_FD2, uses-end-to-end-protection=true, alive-timeout=0.2, enable-update=true, handle-never-received=true, init-value=fields=[ABSActv_0x137:0, ABSFailSts_0x137:1, CheckSum_ABS3_0x137:0, dummy_ESP_FD2_37:0, dummy_ESP_FD2_38:0, dummy_ESP_FD2_39:0, dummy_ESP_FD2_40:0, EBDActv_0x137:0, EBDFailSts_0x137:0, RollingCounter_ABS3_0x137:0, VehOdoInfo_0x137:0, VehOdoInfoSts_0x137:1, VehSpd_0x137:0, VehSpdVld_0x137:0]}, required-interface=SG_ABS3_ESP_FD2
    provide port HUT_IP1_0x293: nonqueued-sender-com-spec{data-element=HUT_IP1_0x293, init-value=8 x 0}, provided-interface=HUT_IP1_0x293
    provide port HUT_IP3_0x34A: nonqueued-sender-com-spec{data-element=HUT_IP3_0x34A, init-value=16 x 0}, provided-interface=HUT_IP3_0x34A
    8 x require port:
      SG_ACC7_ACC_FD2: nonqueued-receiver-com-spec{data-element=SG_ACC7_ACC_FD2, uses-end-to-end-protection=true, alive-timeout=1, enable-update=true, handle-never-received=true, init-value=fields=[ACC_LeTargrtDection:0, ACC_LeTgtDx:0, ACC_LeTgtDy:0, ACC_LeTgtTyp:0, ACC_RiTargrtDetn:0, ACC_RiTgtDx:0, ACC_RiTgtDy:0, ACC_RiTgtTyp:0, Checksum_ACC7:0, dummy_ACC_FD2_19:0, dummy_ACC_FD2_20:0, Request_driveoff:0, RollingCounter_ACC7:0]}, required-interface=SG_ACC7_ACC_FD2
      T_Box_SysErrSts: nonqueued-receiver-com-spec{data-element=T_Box_SysErrSts, init-value=0}, required-interface=T_Box_SysErrSts
      BSD_LCA_warningReqleft: nonqueued-receiver-com-spec{data-element=BSD_LCA_warningReqleft, init-value=0}, required-interface=BSD_LCA_warningReqleft
      BSD_LCA_warningReqRight: nonqueued-receiver-com-spec{data-element=BSD_LCA_warningReqRight, init-value=0}, required-interface=BSD_LCA_warningReqRight
      RCTA_warningReqLeft: nonqueued-receiver-com-spec{data-element=RCTA_warningReqLeft, init-value=0}, required-interface=RCTA_warningReqLeft
      RCTA_warningReqRight: nonqueued-receiver-com-spec{data-element=RCTA_warningReqRight, init-value=0}, required-interface=RCTA_warningReqRight
      DOW_warningReqleft: nonqueued-receiver-com-spec{data-element=DOW_warningReqleft, init-value=0}, required-interface=DOW_warningReqleft
      DOW_warningReqRight: nonqueued-receiver-com-spec{data-element=DOW_warningReqRight, init-value=0}, required-interface=DOW_warningReqRight
    provide port SwToFieldCalRstCmd: nonqueued-sender-com-spec{data-element=SwToFieldCalRstCmd, init-value=0}, provided-interface=SwToFieldCalRstCmd
    provide port SyncRequestMessageId: nonqueued-sender-com-spec{data-element=SyncRequestMessageId, init-value=0}, provided-interface=SyncRequestMessageId
    provide port SyncRequstReseverData1: nonqueued-sender-com-spec{data-element=SyncRequstReseverData1, init-value=7 x 0}, provided-interface=SyncRequstReseverData1
    require port DCT3_0xA6: nonqueued-receiver-com-spec{data-element=DCT3_0xA6, init-value=8 x 0}, required-interface=DCT3_0xA6
    require port ECM11_0x2D3: nonqueued-receiver-com-spec{data-element=ECM11_0x2D3, init-value=8 x 0}, required-interface=ECM11_0x2D3
    provide port SG_HUT32: nonqueued-sender-com-spec{data-element=SG_HUT32, uses-end-to-end-protection=true, init-value=fields=[CheckSum_HUT32:0, ContnPrkgReq:0, ContnPrkgReqValid:0, DetVideoLost:0, PrkgCtrlModReq:0, PrkgCtrlModReqValid:0, PrkStraightContinueReq_HUT:0, PrkStraightModSel_HUT:0, PrkStraightStrtReq_HUT:0, PrkStraightSts_HUT:0, PrkStraightSuspendOrFinishReq_HUT:0, PrkStraightSwtReq_HUT:0, PrkStraightVehStrtReq_HUT_Valid:0, RollingCounter_HUT32:0, ScrnOpSts:0, VolLampDispSts:0, XLvl:2047, YLvl:2047]}, provided-interface=SG_HUT32
    10 x require port:
      AdjVolUpSwtSts: nonqueued-receiver-com-spec{data-element=AdjVolUpSwtSts, init-value=0}, required-interface=AdjVolUpSwtSts
      PageUpSwtSts: nonqueued-receiver-com-spec{data-element=PageUpSwtSts, init-value=0}, required-interface=PageUpSwtSts
      ACC_FD4_0x2B8: nonqueued-receiver-com-spec{data-element=ACC_FD4_0x2B8, alive-timeout=1, enable-update=true, handle-never-received=true, init-value=64 x 0}, required-interface=ACC_FD4_0x2B8
      SG_ACC6_ACC_FD2: nonqueued-receiver-com-spec{data-element=SG_ACC6_ACC_FD2, uses-end-to-end-protection=true, alive-timeout=1, enable-update=true, handle-never-received=true, init-value=fields=[ACC_EgoStatus:0, ACC_PotentialTgtDetn:0, ACC_PotentialTgtDx:0, ACC_PotentialTgtDy:0, ACC_PotentialTgtTyp:0, ACC_RlvTgtDetn:0, ACC_RlvTgtDx:0, ACC_RlvTgtDy:0, ACC_RlvTgtTyp:0, Checksum_ACC6:0, dummy_ACC_FD2_16:0, dummy_ACC_FD2_17:0, dummy_ACC_FD2_18:0, RollingCounter_ACC6:0]}, required-interface=SG_ACC6_ACC_FD2
      SG_BMS4: nonqueued-receiver-com-spec{data-element=SG_BMS4, uses-end-to-end-protection=true, alive-timeout=0.1, enable-update=true, handle-never-received=true, init-value=fields=[BMS_BattPoweErr:0, BMS_ErrCategory:0, BMS_PackCurr:0, BMS_PackVolt:178, BMS_PowerDownCmplt:0, CheckSum_BMS4:0, dummy_BMS4_0:0, dummy_BMS4_1:0, dummy_BMS4_2:0, dummy_BMS4_3:0, dummy_BMS4_4:0, RollingCounter_BMS4:0]}, required-interface=SG_BMS4
      SG_HCU_HP5: nonqueued-receiver-com-spec{data-element=SG_HCU_HP5, uses-end-to-end-protection=true, alive-timeout=0.5, enable-update=true, handle-never-received=true, init-value=fields=[Checksum_HCU_HP5:0, DrvFaiMsg_0x201:0, DrvGearDisp:0, DrvGearDispSts_0x201:0, DrvModDisp_0x201:0, DrvModDispSts_0x201:0, dummy_HCU_HP5_0:0, dummy_HCU_HP5_1:0, dummy_HCU_HP5_2:0, dummy_HCU_HP5_3:0, dummy_HCU_HP5_4:0, HCU_EnrgFlowInd_DHT:0, HCU_PrsBrkWarn:0, HCU_ShftNotAlwd_Warn:0, RollingCounter_HCU_HP5:0]}, required-interface=SG_HCU_HP5
      SG_HCU_PT4: nonqueued-receiver-com-spec{data-element=SG_HCU_PT4, uses-end-to-end-protection=true, alive-timeout=1, enable-update=true, handle-never-received=true, init-value=fields=[CarWashMode_Sts:0, CarWashMode_StsDisp:0, Checksum_HCU_PT4:0, dummy_HCU_PT4_0:0, dummy_HCU_PT4_1:0, dummy_HCU_PT4_2:0, dummy_HCU_PT4_3:0, dummy_HCU_PT4_4:0, dummy_HCU_PT4_5:0, dummy_HCU_PT4_6:0, dummy_HCU_PT4_7:0, HCU_ACStsReq:2, HCU_BattPowerRedWarn:0, HCU_ConnectChrgLine_Indcn:0, HCU_EgyRecFB:0, HCU_EnerSavePowerMod:0, HCU_InhbChrgInfo:0, HCU_OilTankCoverSts:0, HCU_OPDFail:0, HCU_RefuReq:0, HCU_RemoveChrgLine_Indcn:0, HCU_Shift_P_Indcn:0, HCU_SOCLow_Indcn:0, HCU_WadeModeSetSts:0, OPDParkWarnReq:0, RollingCounter_HCU_PT4:0]}, required-interface=SG_HCU_PT4
      SG_HCU_PT7: nonqueued-receiver-com-spec{data-element=SG_HCU_PT7, uses-end-to-end-protection=true, alive-timeout=0.5, enable-update=true, handle-never-received=true, init-value=fields=[CheckSum_HCU_PT7:0, dummy_HCU_PT7_0:0, dummy_HCU_PT7_1:0, dummy_HCU_PT7_2:0, dummy_HCU_PT7_3:0, dummy_HCU_PT7_4:0, dummy_HCU_PT7_5:0, dummy_HCU_PT7_6:0, HCU_12VSysErr_1:0, HCU_12VSysErr_2:0, HCU_12VSysErrLmpSts:0, HCU_EnrgFlowInd:0, HCU_HybSysErr_1:0, HCU_HybSysErr_2:0, HCU_HybSysErr_3:0, HCU_HybSysErr_4:0, HCU_HybSysErr_5:0, HCU_HybSysErr_6:0, HCU_HybSysErr_7:0, HCU_HybSysErrLmpSts:0, HCU_ModSwtFail:0, HCU_OPDLmpSts:0, HCU_OPDSts:0, HCU_PowerRedWarnLmpCmd:0, HCU_RdyLmpSts:0, RollingCounter_HCU_PT7:0]}, required-interface=SG_HCU_PT7
      SG_DHT_FD1: nonqueued-receiver-com-spec{data-element=SG_DHT_FD1, uses-end-to-end-protection=true, alive-timeout=0.1, enable-update=true, handle-never-received=true, init-value=fields=[CheckSum_DHT1:0, dummy_DHT_FD1_8:0, dummy_DHT_FD1_9:0, dummy_DHT_FD1_10:0, dummy_DHT_FD1_11:0, dummy_DHT_FD1_12:0, dummy_DHT_FD1_13:0, RollingCounter_DHT1:0, TCU_ClutchHotWarning:0, TCU_ErrCategory:0]}, required-interface=SG_DHT_FD1
      SG_IFC6_IFC_FD2: nonqueued-receiver-com-spec{data-element=SG_IFC6_IFC_FD2, uses-end-to-end-protection=true, alive-timeout=0.5, enable-update=true, handle-never-received=true, init-value=fields=[Checksum_IFC6:0, dummy_IFC_FD2_17:0, dummy_IFC_FD2_18:0, dummy_IFC_FD2_19:0, dummy_IFC_FD2_20:0, IFC_NextLeLane_dy:2496, IFC_NextRiLane_dy:2496, RollingCounter_IFC6:0]}, required-interface=SG_IFC6_IFC_FD2
    provide port HUT35_0x1E5: nonqueued-sender-com-spec{data-element=HUT35_0x1E5, init-value=8 x 0}, provided-interface=HUT35_0x1E5
    provide port HUT_FD4_0x1DA: nonqueued-sender-com-spec{data-element=HUT_FD4_0x1DA, init-value=64 x 0}, provided-interface=HUT_FD4_0x1DA
    require port HAP_FD6_0x289: nonqueued-receiver-com-spec{data-element=HAP_FD6_0x289, alive-timeout=1, enable-update=true, handle-never-received=true, init-value=64 x 0}, required-interface=HAP_FD6_0x289
    require port HAP_FD7_0x29B: nonqueued-receiver-com-spec{data-element=HAP_FD7_0x29B, alive-timeout=1, enable-update=true, handle-never-received=true, init-value=64 x 0}, required-interface=HAP_FD7_0x29B
    provide port HUT40_0x2CE: nonqueued-sender-com-spec{data-element=HUT40_0x2CE, init-value=8 x 0}, provided-interface=HUT40_0x2CE
    18 x require port:
      HCM_L1_0x308: nonqueued-receiver-com-spec{data-element=HCM_L1_0x308, alive-timeout=2, enable-update=true, handle-never-received=true, init-value=8 x 0}, required-interface=HCM_L1_0x308
      HCM_R1_0x30D: nonqueued-receiver-com-spec{data-element=HCM_R1_0x30D, alive-timeout=2, enable-update=true, handle-never-received=true, init-value=8 x 0}, required-interface=HCM_R1_0x30D
      BMS22_0x3BF: nonqueued-receiver-com-spec{data-element=BMS22_0x3BF, alive-timeout=10, enable-update=true, handle-never-received=true, init-value=8 x 0}, required-interface=BMS22_0x3BF
      BMS8_0x285: nonqueued-receiver-com-spec{data-element=BMS8_0x285, alive-timeout=1, enable-update=true, handle-never-received=true, init-value=8 x 0}, required-interface=BMS8_0x285
      BMS_FD14_0x1E3: nonqueued-receiver-com-spec{data-element=BMS_FD14_0x1E3, init-value=8 x 0}, required-interface=BMS_FD14_0x1E3
      HCU_FD1_0x60: nonqueued-receiver-com-spec{data-element=HCU_FD1_0x60, alive-timeout=0.1, enable-update=true, handle-never-received=true, init-value=64 x 0}, required-interface=HCU_FD1_0x60
      HCU_HC3_0x268: nonqueued-receiver-com-spec{data-element=HCU_HC3_0x268, alive-timeout=0.5, enable-update=true, handle-never-received=true, init-value=8 x 0}, required-interface=HCU_HC3_0x268
      HCU_HC8_0x1E2: nonqueued-receiver-com-spec{data-element=HCU_HC8_0x1E2, init-value=8 x 0}, required-interface=HCU_HC8_0x1E2
      HCU_HP5_0x201: nonqueued-receiver-com-spec{data-element=HCU_HP5_0x201, alive-timeout=0.5, enable-update=true, handle-never-received=true, init-value=8 x 0}, required-interface=HCU_HP5_0x201
      HCU_HP6_0x11A: nonqueued-receiver-com-spec{data-element=HCU_HP6_0x11A, alive-timeout=0.2, enable-update=true, handle-never-received=true, init-value=8 x 0}, required-interface=HCU_HP6_0x11A
      FPAS_WorkSts: nonqueued-receiver-com-spec{data-element=FPAS_WorkSts, alive-timeout=1, enable-update=true, handle-never-received=true, init-value=0}, required-interface=FPAS_WorkSts
      FPAS_SoundIndcn: nonqueued-receiver-com-spec{data-element=FPAS_SoundIndcn, alive-timeout=1, enable-update=true, handle-never-received=true, init-value=0}, required-interface=FPAS_SoundIndcn
      RPAS_SoundIndcn: nonqueued-receiver-com-spec{data-element=RPAS_SoundIndcn, alive-timeout=1, enable-update=true, handle-never-received=true, init-value=0}, required-interface=RPAS_SoundIndcn
      RPAS_WorkSts: nonqueued-receiver-com-spec{data-element=RPAS_WorkSts, alive-timeout=1, enable-update=true, handle-never-received=true, init-value=0}, required-interface=RPAS_WorkSts
      LADBstatus: nonqueued-receiver-com-spec{data-element=LADBstatus, alive-timeout=2, enable-update=true, handle-never-received=true, init-value=0}, required-interface=LADBstatus
      RADBstatus: nonqueued-receiver-com-spec{data-element=RADBstatus, alive-timeout=2, enable-update=true, handle-never-received=true, init-value=0}, required-interface=RADBstatus
      LHiBeamSts: nonqueued-receiver-com-spec{data-element=LHiBeamSts, alive-timeout=2, enable-update=true, handle-never-received=true, init-value=0}, required-interface=LHiBeamSts
      RHiBeamSts: nonqueued-receiver-com-spec{data-element=RHiBeamSts, alive-timeout=2, enable-update=true, handle-never-received=true, init-value=0}, required-interface=RHiBeamSts
    component Cluster_App: type=Cluster_App
    component BSW_CDD: type=BSW_CDD
    component Manager_Swc: type=Manager_Swc
    delegate Cluster_App.SG_ESP1_ESP_FD2 <-> outer port SG_ESP1_ESP_FD2
    delegate Cluster_App.SG_ESP2 <-> outer port SG_ESP2
    delegate Cluster_App.SG_ESP2_ESP_FD2 <-> outer port SG_ESP2_ESP_FD2
    delegate Cluster_App.SG_ABM1 <-> outer port SG_ABM1
    delegate Cluster_App.SG_AEB2_AEB_FD2 <-> outer port SG_AEB2_AEB_FD2
    delegate Cluster_App.SG_AEB3_AEB_FD2 <-> outer port SG_AEB3_AEB_FD2
    delegate Cluster_App.SG_ACC4_ACC_FD2 <-> outer port SG_ACC4_ACC_FD2
    delegate Cluster_App.SG_EPS1_FD1 <-> outer port SG_EPS1_FD1
    delegate Cluster_App.SG_IFC4_IFC_FD2 <-> outer port SG_IFC4_IFC_FD2
    delegate Cluster_App.SG_HC1 <-> outer port SG_HC1
    delegate Cluster_App.SG_IFC5_IFC_FD2 <-> outer port SG_IFC5_IFC_FD2
    delegate Cluster_App.IFC_FD2_0x23D <-> outer port IFC_FD2_0x23D
    delegate Cluster_App.ABM1_0x351 <-> outer port ABM1_0x351
    delegate Cluster_App.BMS_BattHeatRunaway <-> outer port BMS_BattHeatRunaway
    delegate Cluster_App.GentrWarnLmpSts <-> outer port GentrWarnLmpSts
    delegate Cluster_App.FPAS_SoundIndcn_FD <-> outer port FPAS_SoundIndcn_FD
    delegate Cluster_App.FPAS_WorkSts_FD <-> outer port FPAS_WorkSts_FD
    delegate Cluster_App.TGS_LEVER <-> outer port TGS_LEVER
    delegate Cluster_App.FuelConsumption <-> outer port FuelConsumption
    delegate Cluster_App.FCTA_Warn <-> outer port FCTA_Warn
    delegate Cluster_App.FCTBTrig <-> outer port FCTBTrig
    delegate Cluster_App.CR_BliSts <-> outer port CR_BliSts
    delegate Cluster_App.FCTA_B_FuncSts <-> outer port FCTA_B_FuncSts
    delegate Cluster_App.SG_ACC8_ACC_FD2 <-> outer port SG_ACC8_ACC_FD2
    delegate Cluster_App.SG_IFC3_IFC_FD2 <-> outer port SG_IFC3_IFC_FD2
    delegate Cluster_App.SG_ACC3_ACC_FD2 <-> outer port SG_ACC3_ACC_FD2
    delegate Cluster_App.SG_EPB1 <-> outer port SG_EPB1
    delegate Cluster_App.SG_EPS1 <-> outer port SG_EPS1
    delegate Cluster_App.SG_DCT7 <-> outer port SG_DCT7
    delegate Cluster_App.SG_ABS3 <-> outer port SG_ABS3
    delegate Cluster_App.SG_ESP1 <-> outer port SG_ESP1
    delegate Cluster_App.SG_HUT_IP2 <-> outer port SG_HUT_IP2
    delegate Cluster_App.SG_ABS3_ESP_FD2 <-> outer port SG_ABS3_ESP_FD2
    delegate Cluster_App.SG_ACC7_ACC_FD2 <-> outer port SG_ACC7_ACC_FD2
    delegate Cluster_App.T_Box_SysErrSts <-> outer port T_Box_SysErrSts
    delegate Cluster_App.BSD_LCA_warningReqleft <-> outer port BSD_LCA_warningReqleft
    delegate Cluster_App.BSD_LCA_warningReqRight <-> outer port BSD_LCA_warningReqRight
    delegate Cluster_App.DOW_warningReqleft <-> outer port DOW_warningReqleft
    delegate Cluster_App.DOW_warningReqRight <-> outer port DOW_warningReqRight
    delegate Cluster_App.RCTA_warningReqRight <-> outer port RCTA_warningReqRight
    delegate Cluster_App.RCTA_warningReqLeft <-> outer port RCTA_warningReqLeft
    connect BSW_CDD.HsmKeyM -> Manager_Swc.HsmKeyM
    delegate Manager_Swc.SyncRequstReseverData1 <-> outer port SyncRequstReseverData1
    delegate Manager_Swc.SyncRequestMessageId <-> outer port SyncRequestMessageId
    delegate Cluster_App.DCT3_0xA6 <-> outer port DCT3_0xA6
    delegate Cluster_App.ECM11_0x2D3 <-> outer port ECM11_0x2D3
    delegate Cluster_App.SG_HUT32 <-> outer port SG_HUT32
    delegate Cluster_App.ACC_FD4_0x2B8 <-> outer port ACC_FD4_0x2B8
    delegate Cluster_App.SG_ACC6_ACC_FD2 <-> outer port SG_ACC6_ACC_FD2
    delegate Cluster_App.SG_BMS4 <-> outer port SG_BMS4
    delegate Cluster_App.SG_HCU_HP5 <-> outer port SG_HCU_HP5
    delegate Cluster_App.SG_HCU_PT4 <-> outer port SG_HCU_PT4
    delegate Cluster_App.SG_HCU_PT7 <-> outer port SG_HCU_PT7
    delegate Cluster_App.SG_DHT_FD1 <-> outer port SG_DHT_FD1
    delegate Cluster_App.SG_IFC6_IFC_FD2 <-> outer port SG_IFC6_IFC_FD2
    delegate Cluster_App.HUT35_0x1E5 <-> outer port HUT35_0x1E5
    delegate Cluster_App.HUT_FD4_0x1DA <-> outer port HUT_FD4_0x1DA
    delegate Cluster_App.HAP_FD6_0x289 <-> outer port HAP_FD6_0x289
    delegate Cluster_App.HAP_FD7_0x29B <-> outer port HAP_FD7_0x29B
    delegate Cluster_App.HUT40_0x2CE <-> outer port HUT40_0x2CE
    delegate Cluster_App.HCM_L1_0x308 <-> outer port HCM_L1_0x308
    delegate Cluster_App.HCM_R1_0x30D <-> outer port HCM_R1_0x30D
    delegate Cluster_App.BMS22_0x3BF <-> outer port BMS22_0x3BF
    delegate Cluster_App.BMS8_0x285 <-> outer port BMS8_0x285
    delegate Cluster_App.BMS_FD14_0x1E3 <-> outer port BMS_FD14_0x1E3
    delegate Cluster_App.HCU_FD1_0x60 <-> outer port HCU_FD1_0x60
    delegate Cluster_App.HCU_HC3_0x268 <-> outer port HCU_HC3_0x268
    delegate Cluster_App.HCU_HC8_0x1E2 <-> outer port HCU_HC8_0x1E2
    delegate Cluster_App.HCU_HP5_0x201 <-> outer port HCU_HP5_0x201
    delegate Cluster_App.HCU_HP6_0x11A <-> outer port HCU_HP6_0x11A
    delegate Cluster_App.FPAS_WorkSts <-> outer port FPAS_WorkSts
    delegate Cluster_App.FPAS_SoundIndcn <-> outer port FPAS_SoundIndcn
    delegate Cluster_App.RPAS_SoundIndcn <-> outer port RPAS_SoundIndcn
    delegate Cluster_App.RPAS_WorkSts <-> outer port RPAS_WorkSts
    delegate Cluster_App.LADBstatus <-> outer port LADBstatus
    delegate Cluster_App.RADBstatus <-> outer port RADBstatus
    delegate Cluster_App.LHiBeamSts <-> outer port LHiBeamSts
    delegate Cluster_App.RHiBeamSts <-> outer port RHiBeamSts
package /EndToEndProtections
  end to end protection set EndToEndProtectionSet
    32 x end to end protection:
      ECU_Composition_SG_ESP1_ESP_FD2_SG_ESP1_ESP_FD2: end-to-end-profile={category=PROFILE_01, data-ids=43, data-id-mode=0, data-length=64, max-delta-counter-init=2, crc-offset=0, counter-offset=56, max-no-new-or-repeated-data=14, sync-counter-init=1, data-id-nibble-offset=0}, end-to-end-protection-variable-prototype=receiver=EcuSwComposition.SG_ESP1_ESP_FD2.SG_ESP1_ESP_FD2
      ECU_Composition_SG_ABS3_ESP_FD2_SG_ABS3_ESP_FD2: end-to-end-profile={category=PROFILE_01, data-ids=291, data-id-mode=0, data-length=64, max-delta-counter-init=2, crc-offset=0, counter-offset=56, max-no-new-or-repeated-data=14, sync-counter-init=1, data-id-nibble-offset=0}, end-to-end-protection-variable-prototype=receiver=EcuSwComposition
      ECU_Composition_SG_ESP2_SG_ESP2: end-to-end-profile={category=PROFILE_01, data-ids=44, data-id-mode=0, data-length=64, max-delta-counter-init=2, crc-offset=0, counter-offset=56, max-no-new-or-repeated-data=14, sync-counter-init=1, data-id-nibble-offset=0}, end-to-end-protection-variable-prototype=receiver=EcuSwComposition.SG_ESP2.SG_ESP2
      ECU_Composition_SG_ESP2_ESP_FD2_SG_ESP2_ESP_FD2: end-to-end-profile={category=PROFILE_01, data-ids=44, data-id-mode=0, data-length=64, max-delta-counter-init=2, crc-offset=0, counter-offset=56, max-no-new-or-repeated-data=14, sync-counter-init=1, data-id-nibble-offset=0}, end-to-end-protection-variable-prototype=receiver=EcuSwComposition.SG_ESP2_ESP_FD2.SG_ESP2_ESP_FD2
      ECU_Composition_SG_ABM1_SG_ABM1: end-to-end-profile={category=PROFILE_01, data-ids=58, data-id-mode=0, data-length=64, max-delta-counter-init=2, crc-offset=0, counter-offset=56, max-no-new-or-repeated-data=14, sync-counter-init=1, data-id-nibble-offset=0}, end-to-end-protection-variable-prototype=receiver=EcuSwComposition.SG_ABM1.SG_ABM1
      ECU_Composition_SG_AEB2_AEB_FD2_SG_AEB2_AEB_FD2: end-to-end-profile={category=PROFILE_01, data-ids=91, data-id-mode=0, data-length=64, max-delta-counter-init=2, crc-offset=0, counter-offset=56, max-no-new-or-repeated-data=14, sync-counter-init=1, data-id-nibble-offset=0}, end-to-end-protection-variable-prototype=receiver=EcuSwComposition.SG_AEB2_AEB_FD2.SG_AEB2_AEB_FD2
      ECU_Composition_SG_AEB3_AEB_FD2_SG_AEB3_AEB_FD2: end-to-end-profile={category=PROFILE_01, data-ids=92, data-id-mode=0, data-length=64, max-delta-counter-init=2, crc-offset=0, counter-offset=56, max-no-new-or-repeated-data=14, sync-counter-init=1, data-id-nibble-offset=0}, end-to-end-protection-variable-prototype=receiver=EcuSwComposition.SG_AEB3_AEB_FD2.SG_AEB3_AEB_FD2
      ECU_Composition_SG_ACC4_ACC_FD2_SG_ACC4_ACC_FD2: end-to-end-profile={category=PROFILE_01, data-ids=87, data-id-mode=0, data-length=64, max-delta-counter-init=2, crc-offset=0, counter-offset=56, max-no-new-or-repeated-data=14, sync-counter-init=1, data-id-nibble-offset=0}, end-to-end-protection-variable-prototype=receiver=EcuSwComposition.SG_ACC4_ACC_FD2.SG_ACC4_ACC_FD2
      ECU_Composition_SG_EPS1_FD1_SG_EPS1_FD1: end-to-end-profile={category=PROFILE_01, data-ids=53, data-id-mode=0, data-length=64, max-delta-counter-init=2, crc-offset=0, counter-offset=56, max-no-new-or-repeated-data=14, sync-counter-init=1, data-id-nibble-offset=0}, end-to-end-protection-variable-prototype=receiver=EcuSwComposition.SG_EPS1_FD1.SG_EPS1_FD1
      ECU_Composition_SG_IFC4_IFC_FD2_SG_IFC4_IFC_FD2: end-to-end-profile={category=PROFILE_01, data-ids=80, data-id-mode=0, data-length=64, max-delta-counter-init=2, crc-offset=0, counter-offset=56, max-no-new-or-repeated-data=14, sync-counter-init=1, data-id-nibble-offset=0}, end-to-end-protection-variable-prototype=receiver=EcuSwComposition.SG_IFC4_IFC_FD2.SG_IFC4_IFC_FD2
      ECU_Composition_SG_HC1_SG_HC1: end-to-end-profile={category=PROFILE_01, data-ids=96, data-id-mode=0, data-length=64, max-delta-counter-init=2, crc-offset=0, counter-offset=56, max-no-new-or-repeated-data=14, sync-counter-init=1, data-id-nibble-offset=0}, end-to-end-protection-variable-prototype=receiver=EcuSwComposition.SG_HC1.SG_HC1
      ECU_Composition_SG_IFC5_IFC_FD2_SG_IFC5_IFC_FD2: end-to-end-profile={category=PROFILE_01, data-ids=81, data-id-mode=0, data-length=64, max-delta-counter-init=2, crc-offset=0, counter-offset=56, max-no-new-or-repeated-data=14, sync-counter-init=1, data-id-nibble-offset=0}, end-to-end-protection-variable-prototype=receiver=EcuSwComposition.SG_IFC5_IFC_FD2.SG_IFC5_IFC_FD2
      ECU_Composition_SG_ACC8_ACC_FD2_SG_ACC8_ACC_FD2: end-to-end-profile={category=PROFILE_01, data-ids=109, data-id-mode=0, data-length=64, max-delta-counter-init=2, crc-offset=0, counter-offset=56, max-no-new-or-repeated-data=14, sync-counter-init=1, data-id-nibble-offset=0}, end-to-end-protection-variable-prototype=receiver=EcuSwComposition.SG_ACC8_ACC_FD2.SG_ACC8_ACC_FD2
      ECU_Composition_SG_IFC3_IFC_FD2_SG_IFC3_IFC_FD2: end-to-end-profile={category=PROFILE_01, data-ids=79, data-id-mode=0, data-length=64, max-delta-counter-init=2, crc-offset=0, counter-offset=56, max-no-new-or-repeated-data=14, sync-counter-init=1, data-id-nibble-offset=0}, end-to-end-protection-variable-prototype=receiver=EcuSwComposition.SG_IFC3_IFC_FD2.SG_IFC3_IFC_FD2
      ECU_Composition_SG_ACC3_ACC_FD2_SG_ACC3_ACC_FD2: end-to-end-profile={category=PROFILE_01, data-ids=86, data-id-mode=0, data-length=64, max-delta-counter-init=2, crc-offset=0, counter-offset=56, max-no-new-or-repeated-data=14, sync-counter-init=1, data-id-nibble-offset=0}, end-to-end-protection-variable-prototype=receiver=EcuSwComposition.SG_ACC3_ACC_FD2.SG_ACC3_ACC_FD2
      ECU_Composition_SG_ACC7_ACC_FD2_SG_ACC7_ACC_FD2_1: end-to-end-profile={category=PROFILE_01, data-ids=89, data-id-mode=0, data-length=64, max-delta-counter-init=2, crc-offset=0, counter-offset=56, max-no-new-or-repeated-data=14, sync-counter-init=1, data-id-nibble-offset=0}, end-to-end-protection-variable-prototype=receiver=EcuSwComposition
      ECU_Composition_SG_EPB1_SG_EPB1_1: end-to-end-profile={category=PROFILE_01, data-ids=42, data-id-mode=0, data-length=64, max-delta-counter-init=2, crc-offset=0, counter-offset=56, max-no-new-or-repeated-data=14, sync-counter-init=1, data-id-nibble-offset=0}, end-to-end-protection-variable-prototype=receiver=EcuSwComposition.SG_EPB1.SG_EPB1
      ECU_Composition_SG_EPS1_SG_EPS1_1: end-to-end-profile={category=PROFILE_01, data-ids=53, data-id-mode=0, data-length=64, max-delta-counter-init=2, crc-offset=0, counter-offset=56, max-no-new-or-repeated-data=14, sync-counter-init=1, data-id-nibble-offset=0}, end-to-end-protection-variable-prototype=receiver=EcuSwComposition.SG_EPS1.SG_EPS1
      ECU_Composition_SG_DCT7_SG_DCT7_1: end-to-end-profile={category=PROFILE_01, data-ids=37, data-id-mode=0, data-length=64, max-delta-counter-init=2, crc-offset=0, counter-offset=56, max-no-new-or-repeated-data=14, sync-counter-init=1, data-id-nibble-offset=0}, end-to-end-protection-variable-prototype=receiver=EcuSwComposition.SG_DCT7.SG_DCT7
      ECU_Composition_SG_ABS3_SG_ABS3_2: end-to-end-profile={category=PROFILE_01, data-ids=40, data-id-mode=0, data-length=64, max-delta-counter-init=2, crc-offset=0, counter-offset=56, max-no-new-or-repeated-data=14, sync-counter-init=1, data-id-nibble-offset=0}, end-to-end-protection-variable-prototype=receiver=EcuSwComposition.SG_ABS3.SG_ABS3
      ECU_Composition_SG_ESP1_SG_ESP1_2: end-to-end-profile={category=PROFILE_01, data-ids=43, data-id-mode=0, data-length=64, max-delta-counter-init=2, crc-offset=0, counter-offset=56, max-no-new-or-repeated-data=14, sync-counter-init=1, data-id-nibble-offset=0}, end-to-end-protection-variable-prototype=receiver=EcuSwComposition.SG_ESP1.SG_ESP1
      ECU_Composition_SG_HUT_IP2_SG_HUT_IP2_2: end-to-end-profile={category=PROFILE_01, data-ids=226, data-id-mode=0, data-length=64, max-delta-counter-init=2, crc-offset=0, counter-offset=56, max-no-new-or-repeated-data=14, sync-counter-init=1, data-id-nibble-offset=0}, end-to-end-protection-variable-prototype=EcuSwComposition.SG_HUT_IP2.SG_HUT_IP2
      ECU_Composition_SG_ABS3_ESP_FD2_SG_ABS3_ESP_FD2_1: end-to-end-profile={category=PROFILE_01, data-ids=40, data-id-mode=0, data-length=64, max-delta-counter-init=2, crc-offset=0, counter-offset=56, max-no-new-or-repeated-data=14, sync-counter-init=1, data-id-nibble-offset=0}, end-to-end-protection-variable-prototype=receiver=EcuSwComposition.SG_ABS3_ESP_FD2.SG_ABS3_ESP_FD2
      ECU_Composition_SG_ACC7_ACC_FD2_SG_ACC7_ACC_FD2: end-to-end-profile={category=PROFILE_01, data-ids=89, data-id-mode=0, data-length=64, max-delta-counter-init=2, crc-offset=0, counter-offset=56, max-no-new-or-repeated-data=14, sync-counter-init=1, data-id-nibble-offset=0}, end-to-end-protection-variable-prototype=receiver=EcuSwComposition.SG_ACC7_ACC_FD2.SG_ACC7_ACC_FD2
      ECU_Composition_SG_HUT32_SG_HUT32: end-to-end-profile={category=PROFILE_01, data-ids=64, data-id-mode=0, data-length=64, max-delta-counter-init=2, crc-offset=0, counter-offset=56, max-no-new-or-repeated-data=14, sync-counter-init=1, data-id-nibble-offset=0}, end-to-end-protection-variable-prototype=EcuSwComposition.SG_HUT32.SG_HUT32
      ECU_Composition_SG_ACC6_ACC_FD2_SG_ACC6_ACC_FD2: end-to-end-profile={category=PROFILE_01, data-ids=88, data-id-mode=0, data-length=64, max-delta-counter-init=2, crc-offset=0, counter-offset=56, max-no-new-or-repeated-data=14, sync-counter-init=1, data-id-nibble-offset=0}, end-to-end-protection-variable-prototype=receiver=EcuSwComposition.SG_ACC6_ACC_FD2.SG_ACC6_ACC_FD2
      ECU_Composition_SG_BMS4_SG_BMS4: end-to-end-profile={category=PROFILE_01, data-ids=11, data-id-mode=0, data-length=64, max-delta-counter-init=2, crc-offset=0, counter-offset=56, max-no-new-or-repeated-data=14, sync-counter-init=1, data-id-nibble-offset=0}, end-to-end-protection-variable-prototype=receiver=EcuSwComposition.SG_BMS4.SG_BMS4
      ECU_Composition_SG_HCU_HP5_SG_HCU_HP5: end-to-end-profile={category=PROFILE_01, data-ids=141, data-id-mode=0, data-length=64, max-delta-counter-init=2, crc-offset=0, counter-offset=56, max-no-new-or-repeated-data=14, sync-counter-init=1, data-id-nibble-offset=0}, end-to-end-protection-variable-prototype=receiver=EcuSwComposition.SG_HCU_HP5.SG_HCU_HP5
      ECU_Composition_SG_HCU_PT4_SG_HCU_PT4: end-to-end-profile={category=PROFILE_01, data-ids=142, data-id-mode=0, data-length=64, max-delta-counter-init=2, crc-offset=0, counter-offset=56, max-no-new-or-repeated-data=14, sync-counter-init=1, data-id-nibble-offset=0}, end-to-end-protection-variable-prototype=receiver=EcuSwComposition.SG_HCU_PT4.SG_HCU_PT4
      ECU_Composition_SG_HCU_PT7_SG_HCU_PT7: end-to-end-profile={category=PROFILE_01, data-ids=140, data-id-mode=0, data-length=64, max-delta-counter-init=2, crc-offset=0, counter-offset=56, max-no-new-or-repeated-data=14, sync-counter-init=1, data-id-nibble-offset=0}, end-to-end-protection-variable-prototype=receiver=EcuSwComposition.SG_HCU_PT7.SG_HCU_PT7
      ECU_Composition_SG_DHT_FD1_SG_DHT_FD1: end-to-end-profile={category=PROFILE_01, data-ids=203, data-id-mode=0, data-length=64, max-delta-counter-init=2, crc-offset=0, counter-offset=56, max-no-new-or-repeated-data=14, sync-counter-init=1, data-id-nibble-offset=0}, end-to-end-protection-variable-prototype=receiver=EcuSwComposition.SG_DHT_FD1.SG_DHT_FD1
      ECU_Composition_SG_IFC6_IFC_FD2_SG_IFC6_IFC_FD2: end-to-end-profile={category=PROFILE_01, data-ids=82, data-id-mode=0, data-length=64, max-delta-counter-init=2, crc-offset=0, counter-offset=56, max-no-new-or-repeated-data=14, sync-counter-init=1, data-id-nibble-offset=0}, end-to-end-protection-variable-prototype=receiver=EcuSwComposition.SG_IFC6_IFC_FD2.SG_IFC6_IFC_FD2
